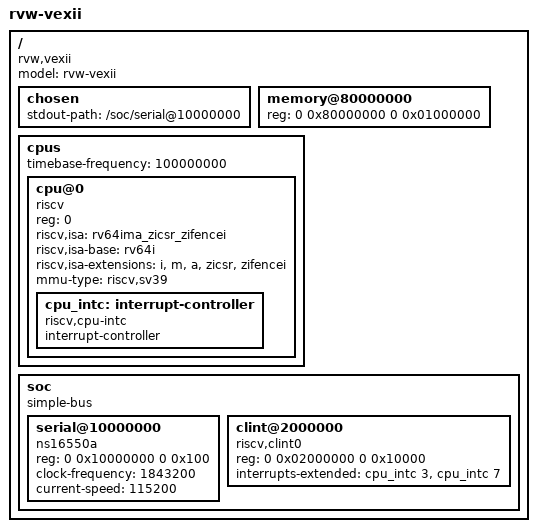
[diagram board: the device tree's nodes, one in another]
/dts-v1/;
/ {
  #address-cells = <2>; #size-cells = <2>;
  compatible = "rvw,vexii"; model = "rvw-vexii";
  chosen { stdout-path = "/soc/serial@10000000"; };
  memory@80000000 { device_type = "memory"; reg = <0 0x80000000 0 0x01000000>; };
  cpus { #address-cells = <1>; #size-cells = <0>; timebase-frequency = <100000000>;
    cpu@0 { device_type = "cpu"; reg = <0>; status = "okay"; compatible = "riscv";
      riscv,isa = "rv64ima_zicsr_zifencei";
      riscv,isa-base = "rv64i";
      riscv,isa-extensions = "i", "m", "a", "zicsr", "zifencei"; mmu-type = "riscv,sv39";
      cpu_intc: interrupt-controller { #interrupt-cells = <1>; interrupt-controller; compatible = "riscv,cpu-intc"; };
    };
  };
  soc { #address-cells = <2>; #size-cells = <2>; compatible = "simple-bus"; ranges;
    serial@10000000 { compatible = "ns16550a"; reg = <0 0x10000000 0 0x100>; clock-frequency = <1843200>; current-speed = <115200>; };
    clint@2000000 { compatible = "riscv,clint0"; reg = <0 0x02000000 0 0x10000>; interrupts-extended = <&cpu_intc 3 &cpu_intc 7>; };
  };
};
